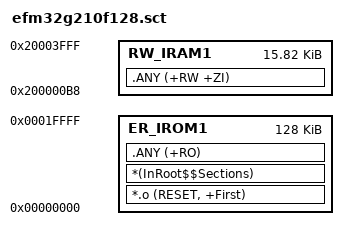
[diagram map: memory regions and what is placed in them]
LR_IROM1 0x00000000 0x20000 {		; load region size_region (128K)

	ER_IROM1 0x00000000 0x20000 {	; load address = execution address
		*.o (RESET, +First)
		*(InRoot$$Sections)
		.ANY (+RO)
	}

	; 46 vectors * 4 bytes = 184 bytes to reserve (0xB8)
	RW_IRAM1 (0x20000000+0xB8) (0x4000-0xB8) {	; RW data
		.ANY (+RW +ZI)
	}
}

